VERSION ""

NS_ :

BS_:

BU_: AD VCU

BO_ 3221225472 VECTOR__INDEPENDENT_SIG_MSG: 0 Vector__XXX
 SG_ AD_ADS_Light : 0|2@1+ (1,0) [0|3] "" Vector__XXX

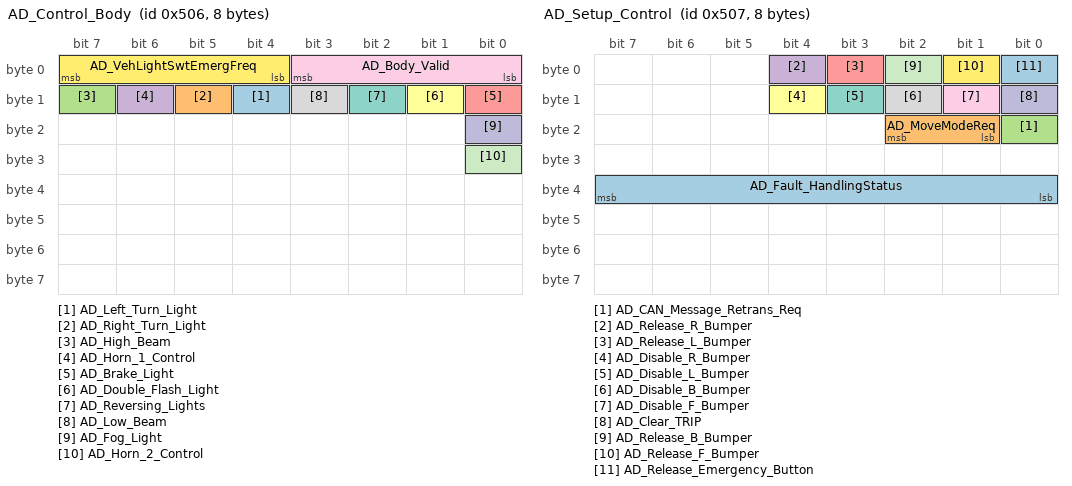
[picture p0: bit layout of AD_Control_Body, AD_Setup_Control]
BO_ 1286 AD_Control_Body: 8 AD
 SG_ AD_Left_Turn_Light : 12|1@1+ (1,0) [0|1] ""  VCU
 SG_ AD_Right_Turn_Light : 13|1@1+ (1,0) [0|1] ""  VCU
 SG_ AD_High_Beam : 15|1@1+ (1,0) [0|1] ""  VCU
 SG_ AD_Horn_1_Control : 14|1@1+ (1,0) [0|1] ""  VCU
 SG_ AD_Brake_Light : 8|1@1+ (1,0) [0|1] ""  VCU
 SG_ AD_Double_Flash_Light : 9|1@1+ (1,0) [0|1] ""  VCU
 SG_ AD_Reversing_Lights : 10|1@1+ (1,0) [0|1] ""  VCU
 SG_ AD_Low_Beam : 11|1@1+ (1,0) [0|1] ""  VCU
 SG_ AD_Body_Valid : 0|4@1+ (1,0) [0|15] ""  VCU
 SG_ AD_Fog_Light : 16|1@1+ (1,0) [0|1] ""  VCU
 SG_ AD_Horn_2_Control : 24|1@1+ (1,0) [0|1] ""  VCU
 SG_ AD_VehLightSwtEmergFreq : 4|4@1+ (1,0) [0|15] "" Vector__XXX

BO_ 1294 AD_OTAReq: 8 AD
 SG_ AD_OTAReq : 0|2@1+ (1,0) [0|3] ""  VCU

BO_ 1288 AD_Control_Device: 8 AD
 SG_ AD_Clean_Fan : 0|1@1+ (1,0) [0|1] ""  VCU

BO_ 1287 AD_Setup_Control: 8 AD
 SG_ AD_Fault_HandlingStatus : 32|8@1+ (1,0) [0|255] ""  VCU
 SG_ AD_MoveModeReq : 17|2@1+ (1,0) [0|3] ""  VCU
 SG_ AD_CAN_Message_Retrans_Req : 16|1@1+ (1,0) [0|1] ""  VCU
 SG_ AD_Release_R_Bumper : 4|1@1+ (1,0) [0|1] ""  VCU
 SG_ AD_Release_L_Bumper : 3|1@1+ (1,0) [0|1] ""  VCU
 SG_ AD_Disable_R_Bumper : 12|1@1+ (1,0) [0|1] ""  VCU
 SG_ AD_Disable_L_Bumper : 11|1@1+ (1,0) [0|1] ""  VCU
 SG_ AD_Disable_B_Bumper : 10|1@1+ (1,0) [0|1] ""  VCU
 SG_ AD_Disable_F_Bumper : 9|1@1+ (1,0) [0|1] ""  VCU
 SG_ AD_Clear_TRIP : 8|1@1+ (1,0) [0|1] ""  VCU
 SG_ AD_Release_B_Bumper : 2|1@1+ (1,0) [0|1] ""  VCU
 SG_ AD_Release_F_Bumper : 1|1@1+ (1,0) [0|1] ""  VCU
 SG_ AD_Release_Emergency_Button : 0|1@1+ (1,0) [0|1] ""  VCU

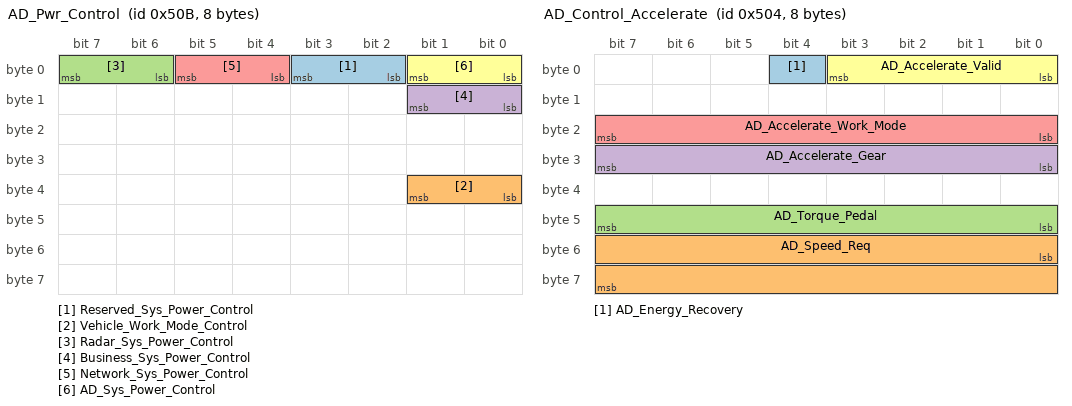
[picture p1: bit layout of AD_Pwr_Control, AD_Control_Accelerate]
BO_ 1291 AD_Pwr_Control: 8 AD
 SG_ Reserved_Sys_Power_Control : 2|2@1+ (1,0) [0|3] ""  VCU
 SG_ Vehicle_Work_Mode_Control : 32|2@1+ (1,0) [0|3] ""  VCU
 SG_ Radar_Sys_Power_Control : 6|2@1+ (1,0) [0|3] ""  VCU
 SG_ Business_Sys_Power_Control : 8|2@1+ (1,0) [0|3] ""  VCU
 SG_ Network_Sys_Power_Control : 4|2@1+ (1,0) [0|3] ""  VCU
 SG_ AD_Sys_Power_Control : 0|2@1+ (1,0) [0|3] ""  VCU

BO_ 1290 AD_VCU_Pwr_Control: 8 AD
 SG_ AD_PwrDownCountInit : 8|6@1+ (1,0) [0|63] "S"  VCU
 SG_ AD_Vehicle_PwrReq : 0|8@1+ (1,0) [0|255] ""  VCU

BO_ 1284 AD_Control_Accelerate: 8 AD
 SG_ AD_Energy_Recovery : 4|1@1+ (1,0) [0|1] ""  VCU
 SG_ AD_Speed_Req : 48|16@1+ (0.1,0) [0|80] "km/h"  VCU
 SG_ AD_Torque_Pedal : 40|8@1+ (1,0) [0|100] "%"  VCU
 SG_ AD_Accelerate_Gear : 24|8@1+ (1,0) [0|3] ""  VCU
 SG_ AD_Accelerate_Work_Mode : 16|8@1+ (1,0) [0|2] ""  VCU
 SG_ AD_Accelerate_Valid : 0|4@1+ (1,0) [0|15] ""  VCU

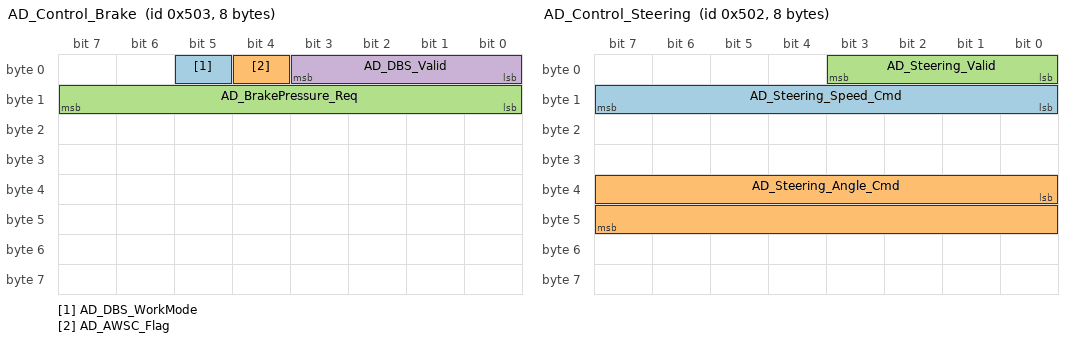
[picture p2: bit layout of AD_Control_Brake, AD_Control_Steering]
BO_ 1283 AD_Control_Brake: 8 AD
 SG_ AD_DBS_WorkMode : 5|1@1+ (1,0) [0|1] ""  VCU
 SG_ AD_AWSC_Flag : 4|1@1+ (1,0) [0|1] ""  VCU
 SG_ AD_BrakePressure_Req : 8|8@1+ (1,0) [0|100] "%"  VCU
 SG_ AD_DBS_Valid : 0|4@1+ (1,0) [0|15] ""  VCU

BO_ 1282 AD_Control_Steering: 8 AD
 SG_ AD_Steering_Speed_Cmd : 8|8@1+ (0.1,3.5) [3.5|29] "deg/s"  VCU
 SG_ AD_Steering_Angle_Cmd : 32|16@1+ (0.1,-35) [-35|35] "deg"  VCU
 SG_ AD_Steering_Valid : 0|4@1+ (1,0) [0|15] ""  VCU

CM_ BO_ 3221225472 "This is a message for not used signals, created by Vector CANdb++ DBC OLE DB Provider.";
CM_ SG_ 3221225472 AD_ADS_Light "ADS灯控制使能
0x0：ADS灯灭
0x1：Reserve
0x2：ADS灯亮";
CM_ BO_ 1286 "AD模式下body请求
由AD节点发送，由VCU节点接收";
CM_ SG_ 1286 AD_Left_Turn_Light "AD左转灯控制使能
0x0：左转灯灭
0x1：左转灯亮";
CM_ SG_ 1286 AD_Right_Turn_Light "AD右转灯控制使能
0x0：右转灯灭
0x1：右转灯亮";
CM_ SG_ 1286 AD_High_Beam "AD远光灯控制使能
0x0：远光灯灭
0x1：远光灯亮";
CM_ SG_ 1286 AD_Horn_1_Control "AD内置喇叭控制使能
0x0：低速报警器内置喇叭关
0x1：低速报警器内置喇叭开";
CM_ SG_ 1286 AD_Brake_Light "AD制动灯使能
0x0：制动灯灭
0x1：制动灯亮";
CM_ SG_ 1286 AD_Double_Flash_Light "AD双闪灯控制使能
0x0：双闪灯关
0x1：双闪灯开";
CM_ SG_ 1286 AD_Reversing_Lights "AD倒车灯控制使能
0x0：倒车灯灭
0x1：倒车灯亮";
CM_ SG_ 1286 AD_Low_Beam "AD近光灯控制使能
0x0：近光灯灭
0x1：近光灯亮";
CM_ SG_ 1286 AD_Body_Valid "AD车身部件控制使能
0x0：车身部件去使能
0x1：车身部件使能";
CM_ SG_ 1286 AD_Fog_Light "AD雾灯控制使能
0x0：雾灯灭
0x1：雾灯亮";
CM_ SG_ 1286 AD_Horn_2_Control "AD车载大喇叭控制使能
0x0:车载大喇叭关
0x1:车载大喇叭开";
CM_ SG_ 1286 AD_VehLightSwtEmergFreq "双闪频率
0x0:1.5hz
0x1:3hz
0x2:4hz
0x3:5hz";
CM_ BO_ 1294 "AD请求OTA";
CM_ SG_ 1294 AD_OTAReq "0x0:无效
0x1:请求OTA";
CM_ BO_ 1288 "AD部件请求";
CM_ SG_ 1288 AD_Clean_Fan "清洁风机开关：
0：不开启
1：开启";
CM_ BO_ 1287 "解除急停和Bumper，清除小计里程";
CM_ SG_ 1287 AD_Fault_HandlingStatus "AD故障处理状态
00 无故障控制状态
01 车速限制L控制状态
02 车速限制M控制状态
03 车速限制H控制状态
04 靠边停车控制状态进行中
05 靠边停车控制状态完成
06 靠边停车+车速限制L控制状态进行中
07 靠边停车+车速限制L控制状态完成
08 靠边停车+车速限制M控制状态进行中
09 靠边停车+车速限制M控制状态完成
0A 靠边停车+车速限制H控制状态进行中
0B 靠边停车+车速限制H控制状态完成
0C 滑行停车控制状态进行中
0D 滑行停车控制状态完成";
CM_ SG_ 1287 AD_MoveModeReq "自动驾驶控制车辆挪车模式";
CM_ SG_ 1287 AD_CAN_Message_Retrans_Req "转发信号开启标志
0：转发
1：不转发";
CM_ SG_ 1287 AD_Release_R_Bumper "0x0：无效
0x1：解除右Bumper";
CM_ SG_ 1287 AD_Release_L_Bumper "0x0：无效
0x1：解除左Bumper";
CM_ SG_ 1287 AD_Disable_R_Bumper "0x0：无效
0x1：禁用右Bumper";
CM_ SG_ 1287 AD_Disable_L_Bumper "0x0：无效
0x1：禁用左Bumper";
CM_ SG_ 1287 AD_Disable_B_Bumper "0x0：无效
0x1：禁用后Bumper";
CM_ SG_ 1287 AD_Disable_F_Bumper "0x0：无效
0x1：禁用前Bumper";
CM_ SG_ 1287 AD_Clear_TRIP "0无效，1清除小里程
";
CM_ SG_ 1287 AD_Release_B_Bumper "0x0：无效
0x1：解除后Bumper";
CM_ SG_ 1287 AD_Release_F_Bumper "0x0：无效
0x1：解除前Bumper";
CM_ SG_ 1287 AD_Release_Emergency_Button "0x0：无效
0x1：解除急停按钮";
CM_ BO_ 1291 "自动驾驶系统、补盲雷达系统，业务系统、监控系统、4G网络系统上下电控制
";
CM_ SG_ 1291 Reserved_Sys_Power_Control "预留系统上下电控制  默认上电
0：下电
1：上电
2：保持
3：重启";
CM_ SG_ 1291 Vehicle_Work_Mode_Control "默认不发为正常工作模式
0x0：正常工作模式
0x1：临时停车
0x2：长时间停车";
CM_ SG_ 1291 Radar_Sys_Power_Control "补盲雷达系统上下电控制 默认上电
0下电，1上电，2保持，3重启";
CM_ SG_ 1291 Business_Sys_Power_Control "业务系统上下电控制 默认上电
0：下电
1：上电
2：保持
3：重启";
CM_ SG_ 1291 Network_Sys_Power_Control "4G网络系统上下电控制  默认上电
0x0：下电
0x1：上电
0x2：保持
0x3：重启";
CM_ SG_ 1291 AD_Sys_Power_Control "自动驾驶系统上下电控制 默认上电
0下电，1上电，2保持";
CM_ BO_ 1290 "远程上电信号";
CM_ SG_ 1290 AD_PwrDownCountInit "下电倒计时配置
0约定为30s；无0x50A约定为5s";
CM_ SG_ 1290 AD_Vehicle_PwrReq "底盘总电源
0：关机（底盘、货箱系统均断电）
1：开机（底盘、货箱系统均上电）
2：保持底盘当前状态
3：重启（只能在底盘上电的情况下发重启才会生效）
4：跳过下电倒计时（在下电倒计时阶段发送可跳过）
";
CM_ BO_ 1284 "AD驱动请求
由AD节点发送，由VCU节点接收";
CM_ SG_ 1284 AD_Energy_Recovery "能量回收标志位
0x0：无效
0x1：启用能量回收";
CM_ SG_ 1284 AD_Speed_Req "车辆请求车速（km/h）";
CM_ SG_ 1284 AD_Torque_Pedal "油门踏板（0~100%），对应0-65Nm";
CM_ SG_ 1284 AD_Accelerate_Gear "AD请求档位
0x0：P驻车档 
0x1：D前进档
0x2：N空档
0x3：R后退档";
CM_ SG_ 1284 AD_Accelerate_Work_Mode "AD请求控制模式
0x0：扭矩控制
0x1：速度控制
0x2：加速度控制";
CM_ SG_ 1284 AD_Accelerate_Valid "AD纵向控制使能
0x0：自动驾驶去使能
0x1：自动驾驶使能";
CM_ BO_ 1283 "AD制动请求
由AD节点发送，由VCU节点接收";
CM_ SG_ 1283 AD_DBS_WorkMode "AD控制排气模式接口";
CM_ SG_ 1283 AD_AWSC_Flag "EPB单边打滑标志位
0：未开启
1：开启";
CM_ SG_ 1283 AD_BrakePressure_Req "制动踏板（0~100%），对应0-10Mpa压力请求";
CM_ SG_ 1283 AD_DBS_Valid "AD制动控制使能
0x0：无效
0x1：自驾制动可控";
CM_ BO_ 1282 "AD转向请求
由AD节点发送，由VCU节点接收";
CM_ SG_ 1282 AD_Steering_Speed_Cmd "轮端转向角速度控制";
CM_ SG_ 1282 AD_Steering_Angle_Cmd "AD模式下，-35到+35度 转角请求（左正右负）";
CM_ SG_ 1282 AD_Steering_Valid "AD横向控制使能
0x0：无效
0x1：自驾转向使能";
BA_DEF_ BO_  "GenMsgCycleTime" INT 0 0;
BA_DEF_ BO_  "GenMsgSendType" ENUM  "Cyclic","not_used","not_used","not_used","not_used","Cyclic","not_used","IfActive","NoMsgSendType";
BA_DEF_  "DBName" STRING ;
BA_DEF_  "BusType" STRING ;
BA_DEF_DEF_  "GenMsgCycleTime" 0;
BA_DEF_DEF_  "GenMsgSendType" "Cyclic";
BA_DEF_DEF_  "DBName" "";
BA_DEF_DEF_  "BusType" "CAN";
BA_ "DBName" "W2_CAN2_AD";
BA_ "GenMsgCycleTime" BO_ 1286 20;
BA_ "GenMsgCycleTime" BO_ 1294 100;
BA_ "GenMsgCycleTime" BO_ 1288 20;
BA_ "GenMsgCycleTime" BO_ 1287 20;
BA_ "GenMsgCycleTime" BO_ 1291 20;
BA_ "GenMsgCycleTime" BO_ 1290 20;
BA_ "GenMsgSendType" BO_ 1290 7;
BA_ "GenMsgCycleTime" BO_ 1284 20;
BA_ "GenMsgCycleTime" BO_ 1283 20;
BA_ "GenMsgCycleTime" BO_ 1282 20;
VAL_ 3221225472 AD_ADS_Light 2 "Enable" 0 "Disable" ;
VAL_ 1286 AD_Left_Turn_Light 1 "Enable" 0 "Disable" ;
VAL_ 1286 AD_Right_Turn_Light 1 "Enable" 0 "Disable" ;
VAL_ 1286 AD_High_Beam 1 "Enable" 0 "Disable" ;
VAL_ 1286 AD_Horn_1_Control 1 "Enable" 0 "Disable" ;
VAL_ 1286 AD_Brake_Light 1 "Enable" 0 "Disable" ;
VAL_ 1286 AD_Double_Flash_Light 1 "Enable" 0 "Disable" ;
VAL_ 1286 AD_Reversing_Lights 1 "Enable" 0 "Disable" ;
VAL_ 1286 AD_Low_Beam 1 "Enable" 0 "Disable" ;
VAL_ 1286 AD_Body_Valid 1 "Valid" 0 "Invalid" ;
VAL_ 1286 AD_Fog_Light 1 "Enable" 0 "Disable" ;
VAL_ 1286 AD_Horn_2_Control 1 "Enable" 0 "Disable" ;
VAL_ 1286 AD_VehLightSwtEmergFreq 3 "5Hz" 2 "4Hz" 1 "3Hz" 0 "1.5Hz" ;
VAL_ 1294 AD_OTAReq 1 "自驾OTA请求" 0 "无效" ;
VAL_ 1288 AD_Clean_Fan 1 "Valid" 0 "Invalid" ;
VAL_ 1287 AD_Fault_HandlingStatus 13 "滑行停车控制状态完成" 12 "滑行停车控制状态进行中" 11 "靠边停车+车速限制H控制状态完成" 10 "靠边停车+车速限制H控制状态进行中" 9 "靠边停车+车速限制M控制状态完成" 8 "靠边停车+车速限制M控制状态进行中" 7 "靠边停车+车速限制L控制状态完成" 6 "靠边停车+车速限制L控制状态进行中" 5 "靠边停车控制状态完成" 4 "靠边停车控制状态进行中" 3 "车速限制H控制状态" 2 "车速限制M控制状态" 1 "车速限制L控制状态" 0 "无故障控制状态" ;
VAL_ 1287 AD_MoveModeReq 1 "Valid" 0 "Invalid" ;
VAL_ 1287 AD_CAN_Message_Retrans_Req 1 "不转发" 0 "转发" ;
VAL_ 1287 AD_Release_R_Bumper 1 "解除触碰条" 0 "保持" ;
VAL_ 1287 AD_Release_L_Bumper 1 "解除触碰条" 0 "保持" ;
VAL_ 1287 AD_Disable_R_Bumper 1 "禁用触碰条" 0 "保持" ;
VAL_ 1287 AD_Disable_L_Bumper 1 "禁用触碰条" 0 "保持" ;
VAL_ 1287 AD_Disable_B_Bumper 1 "禁用触碰条" 0 "保持" ;
VAL_ 1287 AD_Disable_F_Bumper 1 "禁用触碰条" 0 "保持" ;
VAL_ 1287 AD_Clear_TRIP 1 "Valid" 0 "Invalid" ;
VAL_ 1287 AD_Release_B_Bumper 1 "解除触碰条" 0 "保持" ;
VAL_ 1287 AD_Release_F_Bumper 1 "解除触碰条" 0 "保持" ;
VAL_ 1287 AD_Release_Emergency_Button 1 "解除急停" 0 "保持" ;
VAL_ 1291 Reserved_Sys_Power_Control 3 "重启" 2 "保持" 1 "上电" 0 "下电" ;
VAL_ 1291 Vehicle_Work_Mode_Control 2 "长时间停车" 1 "临时停车" 0 "正常" ;
VAL_ 1291 Radar_Sys_Power_Control 3 "重启" 2 "保持" 1 "上电" 0 "下电" ;
VAL_ 1291 Business_Sys_Power_Control 3 "重启" 2 "保持" 1 "上电" 0 "下电" ;
VAL_ 1291 Network_Sys_Power_Control 3 "重启" 2 "保持" 1 "上电" 0 "下电" ;
VAL_ 1291 AD_Sys_Power_Control 3 "重启" 2 "保持" 1 "上电" 0 "下电" ;
VAL_ 1290 AD_Vehicle_PwrReq 4 "立即下电" 3 "重启" 2 "保持" 1 "开机" 0 "关机" ;
VAL_ 1284 AD_Energy_Recovery 1 "Valid" 0 "Invalid" ;
VAL_ 1284 AD_Accelerate_Gear 3 "R档" 2 "N档" 1 "D档" 0 "P档" ;
VAL_ 1284 AD_Accelerate_Work_Mode 1 "速度模式" 0 "Pedal模式" ;
VAL_ 1284 AD_Accelerate_Valid 1 "Valid" 0 "Invalid" ;
VAL_ 1283 AD_DBS_WorkMode 1 "排气模式" 0 "线控模式" ;
VAL_ 1283 AD_AWSC_Flag 1 "Valid" 0 "Invalid" ;
VAL_ 1283 AD_DBS_Valid 1 "Valid" 0 "Invalid" ;
VAL_ 1282 AD_Steering_Valid 1 "Valid" 0 "Invalid" ;
